# max32570 register map
Vendor: Maxim-Integrated; Series: ARMCM4; File version: 1.0
CPU: CM4 r2p1, little endian, MPU, FPU, 3 interrupt priority bits
Registers are 32-bit, read-write, reset 0x0 unless marked. A register's access mark holds for its fields unless they carry their own. Offsets are from the block's base; [hi:lo] are bit positions; {n}, {i} and the like mark numbered series; 'fields as' and 'values as' point back to an identical list.

## WDT0 — Watchdog Timer 0
Base 0x40003000
Same registers: WDT1 0x40003400
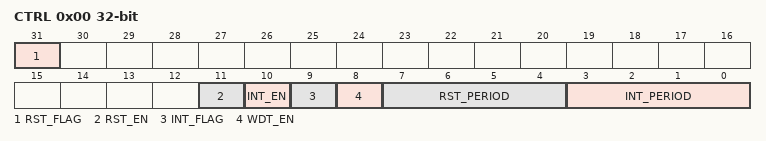
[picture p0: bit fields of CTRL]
0x00 CTRL (reset mask 0x7FFFF000) — Watchdog Timer Control Register.
  [31] RST_FLAG — Watchdog Timer Reset Flag.
    0=noEvent (The event has not occurred.); 1=occurred (The event has occurred.)
  [11] RST_EN — Watchdog Timer Reset Enable.
    0=dis (Disable.); 1=en (Enable.)
  [10] INT_EN — Watchdog Timer Interrupt Enable.
    0=dis (Disable.); 1=en (Enable.)
  [9] INT_FLAG write-1-clears — Watchdog Timer Interrupt Flag.
    0=inactive (No interrupt is pending.); 1=pending (An interrupt is pending.)
  [8] WDT_EN — Watchdog Timer Enable.
    0=dis (Disable.); 1=en (Enable.)
  [7:4] RST_PERIOD — Watchdog Reset Period. The watchdog timer will assert a reset, if enabled, if the CPU does not write the watchdog reset sequence to the WDT_RST register before the watchdog timer has counted this time period since the last timer reset.
    0=wdt2pow31 (2**31 clock cycles.); 1=wdt2pow30 (2**30 clock cycles.); 2=wdt2pow29 (2**29 clock cycles.); 3=wdt2pow28 (2**28 clock cycles.); 4=wdt2pow27 (2^27 clock cycles.); 5=wdt2pow26 (2**26 clock cycles.); 6=wdt2pow25 (2**25 clock cycles.); 7=wdt2pow24 (2**24 clock cycles.); 8=wdt2pow23 (2**23 clock cycles.); 9=wdt2pow22 (2**22 clock cycles.); 10=wdt2pow21 (2**21 clock cycles.); 11=wdt2pow20 (2**20 clock cycles.); 12=wdt2pow19 (2**19 clock cycles.); 13=wdt2pow18 (2**18 clock cycles.); 14=wdt2pow17 (2**17 clock cycles.); 15=wdt2pow16 (2**16 clock cycles.)
  [3:0] INT_PERIOD — Watchdog Interrupt Period. The watchdog timer will assert an interrupt, if enabled, if the CPU does not write the watchdog reset sequence to the WDT_RST register before the watchdog timer has counted this time period since the last timer reset.
    values as RST_PERIOD
0x04 RST wo — Watchdog Timer Reset Register.
  [7:0] WDT_RST — Writing the watchdog counter 'reset sequence' to this register resets the watchdog counter. If the watchdog count exceeds INT_PERIOD then a watchdog interrupt will occur, if enabled. If the watchdog count exceeds RST_PERIOD then a watchdog reset will occur, if enabled.
    165=seq0 (The first value to be written to reset the WDT.); 90=seq1 (The second value to be written to reset the WDT.)

## SKBD — Secure Keyboard
Base 0x40032000
0x00 CR0 — Input Output Select Bits. Each bit of IOSEL selects the pin direction for the corresponding KBDIO pin. If IOSEL[0] = 1, KBDIO0 is an output.
  [9:0] KBDIO_0 — Input Output Select for KBDIO0 pin.
    0=input; 1=output
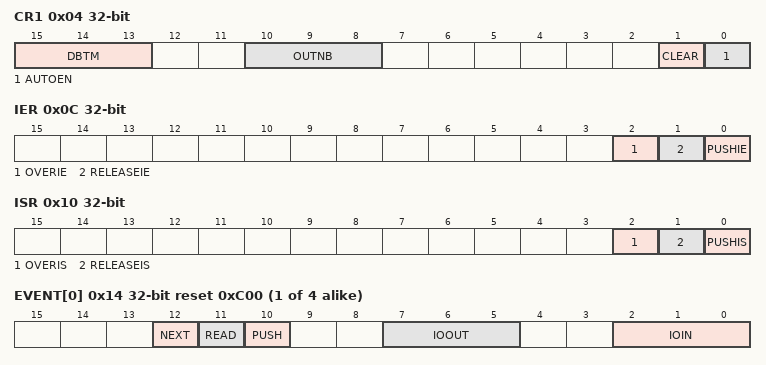
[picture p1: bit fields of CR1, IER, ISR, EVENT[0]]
0x04 CR1 — Control Register 1
  [15:13] DBTM — Debounce Time. Number of milliseconds a keypress event must be active before it is considered actual. NOTE: Debounce time values based on system running from an external 12MHz clock source with PLL0 enabled. Other external crystal values will cause the debounce time to scale linearly.
    0=time4ms (4.1 ms); 1=time5ms (5.3 ms); 2=time6ms (6.5 ms); 3=time7ms (7.6 ms); 4=time8ms (8.8 ms); 5=time10ms (10.0 ms); 6=time11ms (11.2 ms); 7=time12ms (12.3 ms)
  [10:8] OUTNB — Output Number. Number of KBDIO pins selected as outputs. NOTE: Output pins must be allocated contiguously starting with KBDIO0 and continuing through to KBDIO7.
  [1] CLEAR — Auto Clear Bit
    0=disable; 1=enable
  [0] AUTOEN — Automatic Keyboard Scan Enable
    0=disable; 1=enable
0x08 SR ro — Status Register
  [0] BUSY — Busy bit. This bit is set by hardware when the automatic keyboard scan is enabled and running. This bit is clear at all other times.
    0=idle; 1=busy
0x0C IER — Interrupt Enable Register
  [all] fields
    0=disable; 1=enable
  [2] OVERIE — Overrun Event Enable Bit. When set, this bit enables an interrupt to be generated on an overrun event. Automatic keyboard scan must be enabled.
  [1] RELEASEIE — Release Event Enable Bit. When set, this bit enables an interrupt to be generated on a key release event. Automatic keyboard scan must be enabled.
  [0] PUSHIE — Push Event Enable Bit. When set, this bit enables an interrupt to be generated on a key push event. Automatic keyboard scan must be enabled.
0x10 ISR — Interrupt Status Register
  [all] fields
    0=inactive (No interrupt is pending.); 1=pending (An interrupt is pending.)
  [2] OVERIS — Overrun Event Enable Bit. This bit is set by hardware when an overrun event has occurred. If the interrupt is enabled for this flag, a system interrupt will be fired. If the interrupt enable is not set, the flag will be set, but no interrupt will fire. This bit must be cleared by software.
  [1] RELEASEIS — Release Interrupt Flag. This bit is set by hardware when a key has been released. If the interrupt is enabled for this flag, a system interrupt will be fired. If the interrupt enable is not set, the flag will be set, but no interrupt will fire. This bit must be cleared by software.
  [0] PUSHIS — Push Interrupt Flag. This bit is set by hardware when a key has been pushed. If the interrupt is enabled for this flag, a system interrupt will be fired. If the interrupt enable is not set, the flag will be set, but no interrupt will fire. This bit must be cleared by software.
{0x14+4i} EVENT[{i}] (i=0..3) ro reset 0xC00 — Key Register
  [12] NEXT — If set to 1 one of the next key registers (x+1 to 3) contains a key event.
    0=none (No more key register contain a key event.); 1=more (Other key registers contain a key event.)
  [11] READ — If set to 1 this register has been read. If set to 0 the key register has not been read since its last change.
    0=notRead (This register has not been read since its last change.); 1=read (This register has been read.)
  [10] PUSH — If set to 1 the key has been released. If set to 0 the key has been pushed.
    0=pushed; 1=released
  [7:5] IOOUT — IO Output. Output pin of key event.
  [2:0] IOIN — IO Input. Input pin of key event.
